AUTOSAR XML (schema 4.0)
package /ADAS_Components
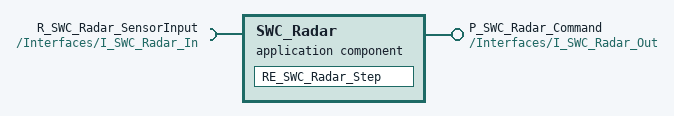
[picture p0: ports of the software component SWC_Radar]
  application sw component type SWC_Radar  # AUTOSAR Application SWC SWC_Radar for ADAS control
    provide port P_SWC_Radar_Command: provided-interface=/Interfaces/I_SWC_Radar_Out
    require port R_SWC_Radar_SensorInput: required-interface=/Interfaces/I_SWC_Radar_In
    behavior SWC_Radar_Behavior
      runnable RE_SWC_Radar_Step: symbol=SWC_Radar_Step
